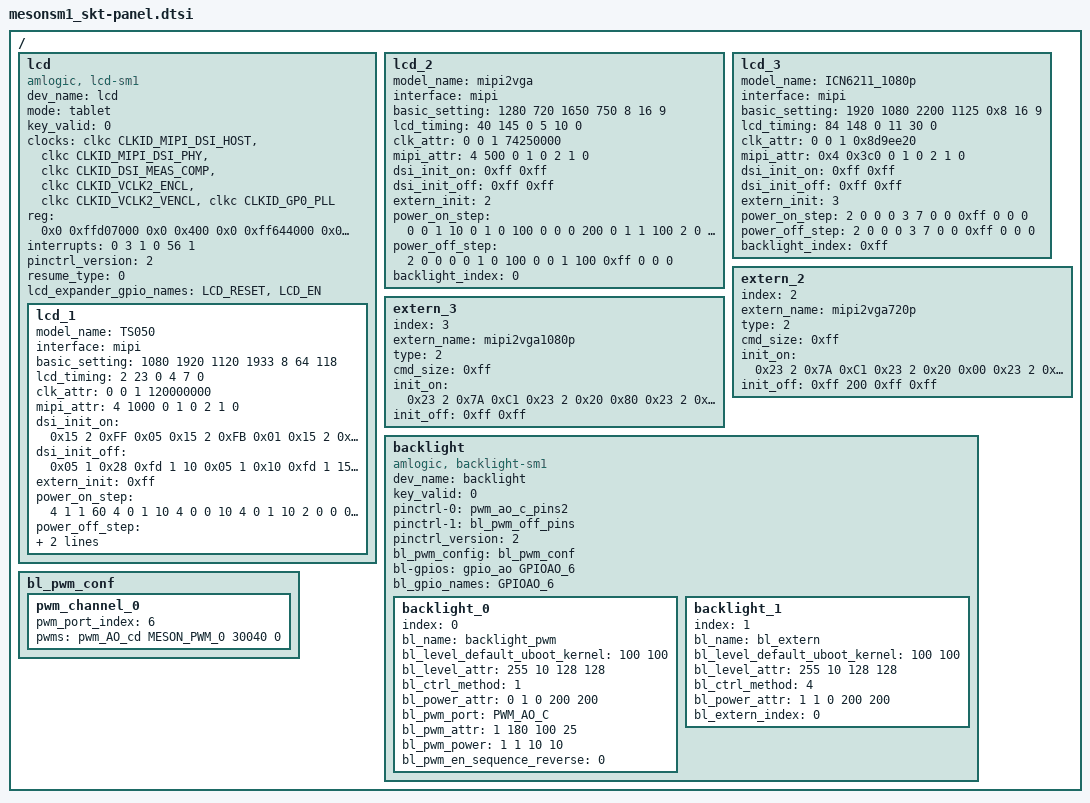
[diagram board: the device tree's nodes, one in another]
/*
 * arch/arm64/boot/dts/amlogic/mesonsm1_skt-panel.dtsi
 *
 * Copyright (C) 2016 Amlogic, Inc. All rights reserved.
 *
 * This program is free software; you can redistribute it and/or modify
 * it under the terms of the GNU General Public License as published by
 * the Free Software Foundation; either version 2 of the License, or
 * (at your option) any later version.
 *
 * This program is distributed in the hope that it will be useful, but WITHOUT
 * ANY WARRANTY; without even the implied warranty of MERCHANTABILITY or
 * FITNESS FOR A PARTICULAR PURPOSE.  See the GNU General Public License for
 * more details.
 *
 */

/ {
	lcd:lcd{
		compatible = "amlogic, lcd-sm1";
		dev_name = "lcd";
		mode = "tablet";
		status = "okay";
		key_valid = <0>;
		clocks = <&clkc CLKID_MIPI_DSI_HOST
			&clkc CLKID_MIPI_DSI_PHY
			&clkc CLKID_DSI_MEAS_COMP
			&clkc CLKID_VCLK2_ENCL
			&clkc CLKID_VCLK2_VENCL
			&clkc CLKID_GP0_PLL>;
		clock-names = "dsi_host_gate",
			"dsi_phy_gate",
			"dsi_meas",
			"encl_top_gate",
			"encl_int_gate",
			"gp0_pll";
		reg = <0x0 0xffd07000 0x0 0x400    /* dsi_host */
			0x0 0xff644000 0x0 0x200>; /* dsi_phy */
		interrupts = <0 3 1
			0 56 1>;
		interrupt-names = "vsync","vsync2";
		pinctrl_version = <2>; /* for uboot */
		resume_type = <0>; /* 0:directly resume(dual display preferred),
				    * 1:workqueue resume(default)
				    */

		/* power type:
		 *    (0=cpu_gpio, 1=pmu_gpio, 2=signal,3=extern, 0xff=ending)
		 * power index:
		 *    (point gpios_index, or extern_index,0xff=invalid)
		 * power value:(0=output low, 1=output high, 2=input)
		 * power delay:(unit in ms)
		 */
		 /*
		lcd_cpu-gpios = <&gpio GPIOH_4 GPIO_ACTIVE_HIGH
				&gpio GPIOH_7 GPIO_ACTIVE_HIGH>;
		lcd_cpu_gpio_names = "GPIOH_4","GPIOH_7";
		*/
		lcd_expander_gpio_names = "LCD_RESET","LCD_EN";


		lcd_1{
			model_name = "TS050";
			interface = "mipi";
			basic_setting = <1080 1920 /*h_active, v_active*/
				1120 1933 /*h_period, v_period*/
				8 /*lcd_bits*/
				64 118>; /*screen_widht, screen_height*/
			lcd_timing = <2 23 0 /*hs_width, hs_bp, hs_pol*/
				4 7 0>; /*vs_width, vs_bp, vs_pol*/
			clk_attr = <0 /*fr_adj_type(0=clk, 1=htotal, 2=vtotal)*/
				0 /*clk_ss_level */
				1 /*clk_auto_generate*/
				120000000>; /*pixel_clk(unit in Hz)*/
			mipi_attr = <4 /*lane_num*/
				1000 /*bit_rate_max(MHz)*/
				0 /*factor(*100, default 0 for auto)*/
				1 /*operation_mode_init(0=video, 1=command)*/
				0 /*operation_mode_display(0=video, 1=command)*/
				2 /*
				   *video_mode_type
				   *(0=sync_pulse,1=sync_event,2=burst)
				   */
				1 /*clk_always_hs(0=disable,1=enable)*/
				0>; /*phy_switch(0=auto,1=standard,2=slow)*/

			/* dsi_init: data_type, num, data... */
			dsi_init_on = <
				0x15 2	0xFF 0x05
				0x15 2	0xFB 0x01
				0x15 2	0xC5 0x01
				0xfd 1 120 /* delay 100ms */

				0x15 2 0xFF 0xEE
				0x15 2 0xFB 0x01
				0x15 2 0x1F 0x45
				0x15 2 0x24 0x4F
				0x15 2 0x38 0xC8
				0x15 2 0x39 0x27
				0x15 2 0x1E 0x77
				0x15 2 0x1D 0x0F
				0x15 2 0x7E 0x71
				0x15 2 0x7C 0x03
				0x15 2 0xFF 0x00
				0x15 2 0xFB 0x01
				0x15 2 0x35 0x01
				0x15 2 0xFF 0x01
				0x15 2 0xFB 0x01
				0x15 2 0x00 0x01
				0x15 2 0x01 0x55
				0x15 2 0x02 0x40
				0x15 2 0x05 0x40
				0x15 2 0x06 0x4A
				0x15 2 0x07 0x24
				0x15 2 0x08 0x0C
				0x15 2 0x0B 0x7D
				0x15 2 0x0C 0x7D
				0x15 2 0x0E 0xB0
				0x15 2 0x0F 0xAE
				0x15 2 0x11 0x10
				0x15 2 0x12 0x10
				0x15 2 0x13 0x03
				0x15 2 0x14 0x4A
				0x15 2 0x15 0x12
				0x15 2 0x16 0x12
				0x15 2 0x18 0x00
				0x15 2 0x19 0x77
				0x15 2 0x1A 0x55
				0x15 2 0x1B 0x13
				0x15 2 0x1C 0x00
				0x15 2 0x1D 0x00
				0x15 2 0x1E 0x13
				0x15 2 0x1F 0x00
				0x15 2 0x23 0x00
				0x15 2 0x24 0x00
				0x15 2 0x25 0x00
				0x15 2 0x26 0x00
				0x15 2 0x27 0x00
				0x15 2 0x28 0x00
				0x15 2 0x35 0x00
				0x15 2 0x66 0x00
				0x15 2 0x58 0x82
				0x15 2 0x59 0x02
				0x15 2 0x5A 0x02
				0x15 2 0x5B 0x02
				0x15 2 0x5C 0x82
				0x15 2 0x5D 0x82
				0x15 2 0x5E 0x02
				0x15 2 0x5F 0x02
				0x15 2 0x72 0x31
				0x15 2 0xFF 0x05
				0x15 2 0xFB 0x01
				0x15 2 0x00 0x01
				0x15 2 0x01 0x0B
				0x15 2 0x02 0x0C
				0x15 2 0x03 0x09
				0x15 2 0x04 0x0A
				0x15 2 0x05 0x00
				0x15 2 0x06 0x0F
				0x15 2 0x07 0x10
				0x15 2 0x08 0x00
				0x15 2 0x09 0x00
				0x15 2 0x0A 0x00
				0x15 2 0x0B 0x00
				0x15 2 0x0C 0x00
				0x15 2 0x0D 0x13
				0x15 2 0x0E 0x15
				0x15 2 0x0F 0x17
				0x15 2 0x10 0x01
				0x15 2 0x11 0x0B
				0x15 2 0x12 0x0C
				0x15 2 0x13 0x09
				0x15 2 0x14 0x0A
				0x15 2 0x15 0x00
				0x15 2 0x16 0x0F
				0x15 2 0x17 0x10
				0x15 2 0x18 0x00
				0x15 2 0x19 0x00
				0x15 2 0x1A 0x00
				0x15 2 0x1B 0x00
				0x15 2 0x1C 0x00
				0x15 2 0x1D 0x13
				0x15 2 0x1E 0x15
				0x15 2 0x1F 0x17
				0x15 2 0x20 0x00
				0x15 2 0x21 0x03
				0x15 2 0x22 0x01
				0x15 2 0x23 0x40
				0x15 2 0x24 0x40
				0x15 2 0x25 0xED
				0x15 2 0x29 0x58
				0x15 2 0x2A 0x12
				0x15 2 0x2B 0x01
				0x15 2 0x4B 0x06
				0x15 2 0x4C 0x11
				0x15 2 0x4D 0x20
				0x15 2 0x4E 0x02
				0x15 2 0x4F 0x02
				0x15 2 0x50 0x20
				0x15 2 0x51 0x61
				0x15 2 0x52 0x01
				0x15 2 0x53 0x63
				0x15 2 0x54 0x77
				0x15 2 0x55 0xED
				0x15 2 0x5B 0x00
				0x15 2 0x5C 0x00
				0x15 2 0x5D 0x00
				0x15 2 0x5E 0x00
				0x15 2 0x5F 0x15
				0x15 2 0x60 0x75
				0x15 2 0x61 0x00
				0x15 2 0x62 0x00
				0x15 2 0x63 0x00
				0x15 2 0x64 0x00
				0x15 2 0x65 0x00
				0x15 2 0x66 0x00
				0x15 2 0x67 0x00
				0x15 2 0x68 0x04
				0x15 2 0x69 0x00
				0x15 2 0x6A 0x00
				0x15 2 0x6C 0x40
				0x15 2 0x75 0x01
				0x15 2 0x76 0x01
				0x15 2 0x7A 0x80
				0x15 2 0x7B 0xA3
				0x15 2 0x7C 0xD8
				0x15 2 0x7D 0x60
				0x15 2 0x7F 0x15
				0x15 2 0x80 0x81
				0x15 2 0x83 0x05
				0x15 2 0x93 0x08
				0x15 2 0x94 0x10
				0x15 2 0x8A 0x00
				0x15 2 0x9B 0x0F
				0x15 2 0xEA 0xFF
				0x15 2 0xEC 0x00
				0x15 2 0xFF 0x01
				0x15 2 0xFB 0x01
				0x15 2 0x75 0x00
				0x15 2 0x76 0xDF
				0x15 2 0x77 0x00
				0x15 2 0x78 0xE4
				0x15 2 0x79 0x00
				0x15 2 0x7A 0xED
				0x15 2 0x7B 0x00
				0x15 2 0x7C 0xF6
				0x15 2 0x7D 0x00
				0x15 2 0x7E 0xFF
				0x15 2 0x7F 0x01
				0x15 2 0x80 0x07
				0x15 2 0x81 0x01
				0x15 2 0x82 0x10
				0x15 2 0x83 0x01
				0x15 2 0x84 0x18
				0x15 2 0x85 0x01
				0x15 2 0x86 0x20
				0x15 2 0x87 0x01
				0x15 2 0x88 0x3D
				0x15 2 0x89 0x01
				0x15 2 0x8A 0x56
				0x15 2 0x8B 0x01
				0x15 2 0x8C 0x84
				0x15 2 0x8D 0x01
				0x15 2 0x8E 0xAB
				0x15 2 0x8F 0x01
				0x15 2 0x90 0xEC
				0x15 2 0x91 0x02
				0x15 2 0x92 0x22
				0x15 2 0x93 0x02
				0x15 2 0x94 0x23
				0x15 2 0x95 0x02
				0x15 2 0x96 0x55
				0x15 2 0x97 0x02
				0x15 2 0x98 0x8B
				0x15 2 0x99 0x02
				0x15 2 0x9A 0xAF
				0x15 2 0x9B 0x02
				0x15 2 0x9C 0xDF
				0x15 2 0x9D 0x03
				0x15 2 0x9E 0x01
				0x15 2 0x9F 0x03
				0x15 2 0xA0 0x2C
				0x15 2 0xA2 0x03
				0x15 2 0xA3 0x39
				0x15 2 0xA4 0x03
				0x15 2 0xA5 0x47
				0x15 2 0xA6 0x03
				0x15 2 0xA7 0x56
				0x15 2 0xA9 0x03
				0x15 2 0xAA 0x66
				0x15 2 0xAB 0x03
				0x15 2 0xAC 0x76
				0x15 2 0xAD 0x03
				0x15 2 0xAE 0x85
				0x15 2 0xAF 0x03
				0x15 2 0xB0 0x90
				0x15 2 0xB1 0x03
				0x15 2 0xB2 0xCB
				0x15 2 0xB3 0x00
				0x15 2 0xB4 0xDF
				0x15 2 0xB5 0x00
				0x15 2 0xB6 0xE4
				0x15 2 0xB7 0x00
				0x15 2 0xB8 0xED
				0x15 2 0xB9 0x00
				0x15 2 0xBA 0xF6
				0x15 2 0xBB 0x00
				0x15 2 0xBC 0xFF
				0x15 2 0xBD 0x01
				0x15 2 0xBE 0x07
				0x15 2 0xBF 0x01
				0x15 2 0xC0 0x10
				0x15 2 0xC1 0x01
				0x15 2 0xC2 0x18
				0x15 2 0xC3 0x01
				0x15 2 0xC4 0x20
				0x15 2 0xC5 0x01
				0x15 2 0xC6 0x3D
				0x15 2 0xC7 0x01
				0x15 2 0xC8 0x56
				0x15 2 0xC9 0x01
				0x15 2 0xCA 0x84
				0x15 2 0xCB 0x01
				0x15 2 0xCC 0xAB
				0x15 2 0xCD 0x01
				0x15 2 0xCE 0xEC
				0x15 2 0xCF 0x02
				0x15 2 0xD0 0x22
				0x15 2 0xD1 0x02
				0x15 2 0xD2 0x23
				0x15 2 0xD3 0x02
				0x15 2 0xD4 0x55
				0x15 2 0xD5 0x02
				0x15 2 0xD6 0x8B
				0x15 2 0xD7 0x02
				0x15 2 0xD8 0xAF
				0x15 2 0xD9 0x02
				0x15 2 0xDA 0xDF
				0x15 2 0xDB 0x03
				0x15 2 0xDC 0x01
				0x15 2 0xDD 0x03
				0x15 2 0xDE 0x2C
				0x15 2 0xDF 0x03
				0x15 2 0xE0 0x39
				0x15 2 0xE1 0x03
				0x15 2 0xE2 0x47
				0x15 2 0xE3 0x03
				0x15 2 0xE4 0x56
				0x15 2 0xE5 0x03
				0x15 2 0xE6 0x66
				0x15 2 0xE7 0x03
				0x15 2 0xE8 0x76
				0x15 2 0xE9 0x03
				0x15 2 0xEA 0x85
				0x15 2 0xEB 0x03
				0x15 2 0xEC 0x90
				0x15 2 0xED 0x03
				0x15 2 0xEE 0xCB
				0x15 2 0xEF 0x00
				0x15 2 0xF0 0xBB
				0x15 2 0xF1 0x00
				0x15 2 0xF2 0xC0
				0x15 2 0xF3 0x00
				0x15 2 0xF4 0xCC
				0x15 2 0xF5 0x00
				0x15 2 0xF6 0xD6
				0x15 2 0xF7 0x00
				0x15 2 0xF8 0xE1
				0x15 2 0xF9 0x00
				0x15 2 0xFA 0xEA
				0x15 2 0xFF 0x02
				0x15 2 0xFB 0x01
				0x15 2 0x00 0x00
				0x15 2 0x01 0xF4
				0x15 2 0x02 0x00
				0x15 2 0x03 0xEF
				0x15 2 0x04 0x01
				0x15 2 0x05 0x07
				0x15 2 0x06 0x01
				0x15 2 0x07 0x28
				0x15 2 0x08 0x01
				0x15 2 0x09 0x44
				0x15 2 0x0A 0x01
				0x15 2 0x0B 0x76
				0x15 2 0x0C 0x01
				0x15 2 0x0D 0xA0
				0x15 2 0x0E 0x01
				0x15 2 0x0F 0xE7
				0x15 2 0x10 0x02
				0x15 2 0x11 0x1F
				0x15 2 0x12 0x02
				0x15 2 0x13 0x22
				0x15 2 0x14 0x02
				0x15 2 0x15 0x54
				0x15 2 0x16 0x02
				0x15 2 0x17 0x8B
				0x15 2 0x18 0x02
				0x15 2 0x19 0xAF
				0x15 2 0x1A 0x02
				0x15 2 0x1B 0xE0
				0x15 2 0x1C 0x03
				0x15 2 0x1D 0x01
				0x15 2 0x1E 0x03
				0x15 2 0x1F 0x2D
				0x15 2 0x20 0x03
				0x15 2 0x21 0x39
				0x15 2 0x22 0x03
				0x15 2 0x23 0x47
				0x15 2 0x24 0x03
				0x15 2 0x25 0x57
				0x15 2 0x26 0x03
				0x15 2 0x27 0x65
				0x15 2 0x28 0x03
				0x15 2 0x29 0x77
				0x15 2 0x2A 0x03
				0x15 2 0x2B 0x85
				0x15 2 0x2D 0x03
				0x15 2 0x2F 0x8F
				0x15 2 0x30 0x03
				0x15 2 0x31 0xCB
				0x15 2 0x32 0x00
				0x15 2 0x33 0xBB
				0x15 2 0x34 0x00
				0x15 2 0x35 0xC0
				0x15 2 0x36 0x00
				0x15 2 0x37 0xCC
				0x15 2 0x38 0x00
				0x15 2 0x39 0xD6
				0x15 2 0x3A 0x00
				0x15 2 0x3B 0xE1
				0x15 2 0x3D 0x00
				0x15 2 0x3F 0xEA
				0x15 2 0x40 0x00
				0x15 2 0x41 0xF4
				0x15 2 0x42 0x00
				0x15 2 0x43 0xFE
				0x15 2 0x44 0x01
				0x15 2 0x45 0x07
				0x15 2 0x46 0x01
				0x15 2 0x47 0x28
				0x15 2 0x48 0x01
				0x15 2 0x49 0x44
				0x15 2 0x4A 0x01
				0x15 2 0x4B 0x76
				0x15 2 0x4C 0x01
				0x15 2 0x4D 0xA0
				0x15 2 0x4E 0x01
				0x15 2 0x4F 0xE7
				0x15 2 0x50 0x02
				0x15 2 0x51 0x1F
				0x15 2 0x52 0x02
				0x15 2 0x53 0x22
				0x15 2 0x54 0x02
				0x15 2 0x55 0x54
				0x15 2 0x56 0x02
				0x15 2 0x58 0x8B
				0x15 2 0x59 0x02
				0x15 2 0x5A 0xAF
				0x15 2 0x5B 0x02
				0x15 2 0x5C 0xE0
				0x15 2 0x5D 0x03
				0x15 2 0x5E 0x01
				0x15 2 0x5F 0x03
				0x15 2 0x60 0x2D
				0x15 2 0x61 0x03
				0x15 2 0x62 0x39
				0x15 2 0x63 0x03
				0x15 2 0x64 0x47
				0x15 2 0x65 0x03
				0x15 2 0x66 0x57
				0x15 2 0x67 0x03
				0x15 2 0x68 0x65
				0x15 2 0x69 0x03
				0x15 2 0x6A 0x77
				0x15 2 0x6B 0x03
				0x15 2 0x6C 0x85
				0x15 2 0x6D 0x03
				0x15 2 0x6E 0x8F
				0x15 2 0x6F 0x03
				0x15 2 0x70 0xCB
				0x15 2 0x71 0x00
				0x15 2 0x72 0x00
				0x15 2 0x73 0x00
				0x15 2 0x74 0x21
				0x15 2 0x75 0x00
				0x15 2 0x76 0x4C
				0x15 2 0x77 0x00
				0x15 2 0x78 0x6B
				0x15 2 0x79 0x00
				0x15 2 0x7A 0x85
				0x15 2 0x7B 0x00
				0x15 2 0x7C 0x9A
				0x15 2 0x7D 0x00
				0x15 2 0x7E 0xAD
				0x15 2 0x7F 0x00
				0x15 2 0x80 0xBE
				0x15 2 0x81 0x00
				0x15 2 0x82 0xCD
				0x15 2 0x83 0x01
				0x15 2 0x84 0x01
				0x15 2 0x85 0x01
				0x15 2 0x86 0x29
				0x15 2 0x87 0x01
				0x15 2 0x88 0x68
				0x15 2 0x89 0x01
				0x15 2 0x8A 0x98
				0x15 2 0x8B 0x01
				0x15 2 0x8C 0xE5
				0x15 2 0x8D 0x02
				0x15 2 0x8E 0x1E
				0x15 2 0x8F 0x02
				0x15 2 0x90 0x30
				0x15 2 0x91 0x02
				0x15 2 0x92 0x52
				0x15 2 0x93 0x02
				0x15 2 0x94 0x88
				0x15 2 0x95 0x02
				0x15 2 0x96 0xAA
				0x15 2 0x97 0x02
				0x15 2 0x98 0xD7
				0x15 2 0x99 0x02
				0x15 2 0x9A 0xF7
				0x15 2 0x9B 0x03
				0x15 2 0x9C 0x21
				0x15 2 0x9D 0x03
				0x15 2 0x9E 0x2E
				0x15 2 0x9F 0x03
				0x15 2 0xA0 0x3D
				0x15 2 0xA2 0x03
				0x15 2 0xA3 0x4C
				0x15 2 0xA4 0x03
				0x15 2 0xA5 0x5E
				0x15 2 0xA6 0x03
				0x15 2 0xA7 0x71
				0x15 2 0xA9 0x03
				0x15 2 0xAA 0x86
				0x15 2 0xAB 0x03
				0x15 2 0xAC 0x94
				0x15 2 0xAD 0x03
				0x15 2 0xAE 0xFA
				0x15 2 0xAF 0x00
				0x15 2 0xB0 0x00
				0x15 2 0xB1 0x00
				0x15 2 0xB2 0x21
				0x15 2 0xB3 0x00
				0x15 2 0xB4 0x4C
				0x15 2 0xB5 0x00
				0x15 2 0xB6 0x6B
				0x15 2 0xB7 0x00
				0x15 2 0xB8 0x85
				0x15 2 0xB9 0x00
				0x15 2 0xBA 0x9A
				0x15 2 0xBB 0x00
				0x15 2 0xBC 0xAD
				0x15 2 0xBD 0x00
				0x15 2 0xBE 0xBE
				0x15 2 0xBF 0x00
				0x15 2 0xC0 0xCD
				0x15 2 0xC1 0x01
				0x15 2 0xC2 0x01
				0x15 2 0xC3 0x01
				0x15 2 0xC4 0x29
				0x15 2 0xC5 0x01
				0x15 2 0xC6 0x68
				0x15 2 0xC7 0x01
				0x15 2 0xC8 0x98
				0x15 2 0xC9 0x01
				0x15 2 0xCA 0xE5
				0x15 2 0xCB 0x02
				0x15 2 0xCC 0x1E
				0x15 2 0xCD 0x02
				0x15 2 0xCE 0x20
				0x15 2 0xCF 0x02
				0x15 2 0xD0 0x52
				0x15 2 0xD1 0x02
				0x15 2 0xD2 0x88
				0x15 2 0xD3 0x02
				0x15 2 0xD4 0xAA
				0x15 2 0xD5 0x02
				0x15 2 0xD6 0xD7
				0x15 2 0xD7 0x02
				0x15 2 0xD8 0xF7
				0x15 2 0xD9 0x03
				0x15 2 0xDA 0x21
				0x15 2 0xDB 0x03
				0x15 2 0xDC 0x2E
				0x15 2 0xDD 0x03
				0x15 2 0xDE 0x3D
				0x15 2 0xDF 0x03
				0x15 2 0xE0 0x4C
				0x15 2 0xE1 0x03
				0x15 2 0xE2 0x5E
				0x15 2 0xE3 0x03
				0x15 2 0xE4 0x71
				0x15 2 0xE5 0x03
				0x15 2 0xE6 0x86
				0x15 2 0xE7 0x03
				0x15 2 0xE8 0x94
				0x15 2 0xE9 0x03
				0x15 2 0xEA 0xFA
				0x15 2 0xFF 0x01
				0x15 2 0xFB 0x01
				0x15 2 0xFF 0x02
				0x15 2 0xFB 0x01
				0x15 2 0xFF 0x04
				0x15 2 0xFB 0x01
				0x15 2 0xFF 0x00
				0x15 2 0xD3 0x0b
				0x15 2 0xD4 0x04

				0x05 1 0x11
				0xfd 1 120 /* delay 120ms */

				0x15 2 0xFF 0x00
				0x15 2 0x35 0x00
				0x05 1 0x29
				0xfd 1 10   /* delay 10ms */
				0xFF 0>;   /*ending*/
			dsi_init_off = <
				0x05 1 0x28 /* display off */
				0xfd 1 10   /* delay 10ms */
				0x05 1 0x10 /* sleep in */
				0xfd 1 150  /* delay 150ms */
				0xff 0>;    /*ending*/

			extern_init = <0xff>; /*0xff for invalid*/

			/* power step: type, index, value, delay(ms) */
			power_on_step = <
				4 1 1 60
				4 0 1 10
				4 0 0 10
				4 0 1 10
				2 0 0 0
				0xff 0 0 0>; /*ending*/
			power_off_step = <
				2 0 0 0
				4 0 0 0
				4 1 0 20
				0xff 0 0 0>; /*ending*/
			backlight_index = <0>;
		};
	};
	
			lcd_2{
			model_name = "mipi2vga";/* mipi2vga */
			interface = "mipi";
			basic_setting = <1280 720 /*h_active, v_active*/
				1650 750 /*h_period, v_period*/
				8 /*lcd_bits*/
				16 9>; /*screen_widht, screen_height*/
			lcd_timing = <40 145  0 /*hs_width,hs_bp,hs_pol*/
				5 10 0>; /*vs_width,vs_bp,vs_pol*/
			clk_attr = <0 /*fr_adj_type(0=clock,1=htotal,2=vtotal)*/
				0 /*clk_ss_level*/
				1 /*clk_auto_generate*/
				74250000>; /*pixel_clk(unit in Hz)*/
			mipi_attr = <4 /*lane_num*/
				500 /*bit_rate_max(MHz)*/
				0 /*factor(*100, default 0 for auto)*/
				1 /*operation_mode_init(0=video, 1=command)*/
				0 /*operation_mode_display(0=video, 1=command)*/
				2 /*
				   *video_mode_type
				   *(0=sync_pulse,1=sync_event,2=burst)
				   */
				1 /*clk_always_hs(0=disable,1=enable)*/
				0>; /*phy_switch(0=auto,1=standard,2=slow)*/
				/* dsi_init: data_type, num, data... */
			dsi_init_on = <0xff 0xff>; /* ending flag */
			dsi_init_off = <0xff 0xff>; /* ending flag */
				/* extern_init: 0xff for invalid */
			extern_init = <2>;
				/* power step: type,index,value,delay(ms) */
			power_on_step = <
					0 0 1 10
					0 1 0 100
					0 0 0 200
					0 1 1 100
					2 0 0 100
					0xff 0 0 0>;
			power_off_step = <
					2 0 0 0
					0 1 0 100
					0 0 1 100
					0xff 0 0 0>;
			backlight_index = <0>;
		};
		lcd_3{
			model_name = "ICN6211_1080p";
			interface = "mipi";
			basic_setting = <1920 1080
				2200 1125
				0x8
				16 9>;
			lcd_timing = <84 148 0 11 30 0>;
			clk_attr = <0 0 1 0x8d9ee20>;
			mipi_attr = <0x4 0x3c0 0 1 0 2 1 0>;
			dsi_init_on = <0xff 0xff>;
			dsi_init_off = <0xff 0xff>;
			extern_init = <3>;
			power_on_step = <
					2 0 0 0
					3 7 0 0
					0xff 0 0 0>;
			power_off_step = <
					2 0 0 0
					3 7 0 0
					0xff 0 0 0>;
			backlight_index = <0xff>;
		};
		extern_2{
			index = <2>;
			extern_name = "mipi2vga720p"; /* mipi2vga */
			status = "okay";
			type = <2>; /* 0=i2c, 1=spi, 2=mipi */
			cmd_size = <0xff>;
			init_on = <
				0x23 2 0x7A 0xC1
				0x23 2 0x20 0x00
				0x23 2 0x21 0xD0
				0x23 2 0x22 0x25
				0x23 2 0x23 0x91
				0x23 2 0x24 0x28
				0x23 2 0x25 0xB9
				0x23 2 0x26 0x00
				0x23 2 0x27 0x0A
				0x23 2 0x28 0x05
				0x23 2 0x29 0x0F
				0x23 2 0x34 0x80
				0x23 2 0x36 0x91
				0x23 2 0xB5 0xA0
				0x23 2 0x5C 0xFF
				0x23 2 0x2A 0x01
				0x23 2 0x56 0x90
				0x23 2 0x6B 0x51
				0x23 2 0x69 0x2E
				0x23 2 0x10 0x55
				0x23 2 0x11 0x88
				0x23 2 0xB6 0x20
				0x23 2 0x51 0x20
				0x23 2 0x09 0x10
				0xff 40
				0xff 0xff>; /*ending*/
			init_off = <
				0xff 200      /* delay 50ms */
				0xff 0xff>; /*ending*/
		};
		extern_3{
			index = <3>;
			extern_name = "mipi2vga1080p"; /* ICN6211 mipi 1080p*/
			status = "okay";
			type = <2>; /* 0=i2c, 1=spi, 2=mipi */
			cmd_size = <0xff>;
			init_on = <
				0x23 2 0x7A 0xC1
				0x23 2 0x20 0x80
				0x23 2 0x21 0x38
				0x23 2 0x22 0x47
				0x23 2 0x23 0x58
				0x23 2 0x24 0x2C
				0x23 2 0x25 0x94
				0x23 2 0x26 0x00
				0x23 2 0x27 0x04
				0x23 2 0x28 0x05
				0x23 2 0x29 0x24
				0x23 2 0x34 0x80
				0x23 2 0x36 0x58
				0x23 2 0xB5 0xA0
				0x23 2 0x5C 0xFF
				0x23 2 0x2A 0x01
				0x23 2 0x56 0x92
				0x23 2 0x6B 0x33
				0x23 2 0x69 0x20
				0x23 2 0x10 0x40
				0x23 2 0x11 0xA8
				0x23 2 0xB6 0x20
				0x23 2 0x51 0x20
				0x23 2 0x09 0x10
				0xff 0xff>; /*ending*/
			init_off = <0xff 0xff>; /*ending*/
		};

	backlight{
		compatible = "amlogic, backlight-sm1";
		dev_name = "backlight";
		status = "okay";
		key_valid = <0>;
		pinctrl-names = "pwm_on", "pwm_off";
		pinctrl-0 = <&pwm_ao_c_pins2>;
		pinctrl-1 = <&bl_pwm_off_pins>;
		pinctrl_version = <2>; /* for uboot */
		bl_pwm_config = <&bl_pwm_conf>;
		bl-gpios = <&gpio_ao GPIOAO_6 GPIO_ACTIVE_HIGH>;
		bl_gpio_names = "GPIOAO_6";


		/* pwm port: PWM_A, PWM_B, PWM_C, PWM_D, PWM_E, PWM_F, PWM_VS*/
		/* power index:(point gpios_index, 0xff=invalid)
		 * power value:(0=output low, 1=output high, 2=input)
		 * power delay:(unit in ms)
		 */

		backlight_0{
			index = <0>;
			bl_name = "backlight_pwm";
			bl_level_default_uboot_kernel = <100 100>;
			bl_level_attr = <255 10 /*max, min*/
				128 128>; /*mid, mid_mapping*/
			bl_ctrl_method = <1>; /* 1=pwm, 2=pwm_combo, 4=extern */
			bl_power_attr = <0 /*en_gpio_index*/
				1 0 /*on_value, off_value*/
				200 200>; /*on_delay(ms), off_delay(ms)*/
			bl_pwm_port = "PWM_AO_C";
			bl_pwm_attr = <1 /*pwm_method*/
				/*pwm_freq(pwm:Hz, pwm_vs:multiple of vs)*/
				180
				100 25>; /*duty_max(%), duty_min(%)*/
			bl_pwm_power = <1 1 /*pwm_gpio_index, pwm_gpio_off*/
				10 10>; /*pwm_on_delay(ms), pwm_off_delay(ms)*/
			bl_pwm_en_sequence_reverse = <0>; /* 1 for reverse */
		};

		backlight_1{
			index = <1>;
			bl_name = "bl_extern";
			bl_level_default_uboot_kernel = <100 100>;
			bl_level_attr = <255 10 /*max, min*/
				128 128>; /*mid, mid_mapping*/
			bl_ctrl_method = <4>; /*1=pwm, 2=pwm_combo, 4=extern*/
			bl_power_attr = <1 /*en_gpio_index*/
				1 0 /*on_value, off_value*/
				200 200>; /*on_delay(ms), off_delay(ms)*/
			bl_extern_index = <0>;
		};
	};
	bl_pwm_conf:bl_pwm_conf{
		pwm_channel_0 {
			pwm_port_index = <6>;
			pwms = <&pwm_AO_cd MESON_PWM_0 30040 0>;
		};
	};

};/* end of panel */

